VERSION ""

NS_ :

BS_:

BU_:

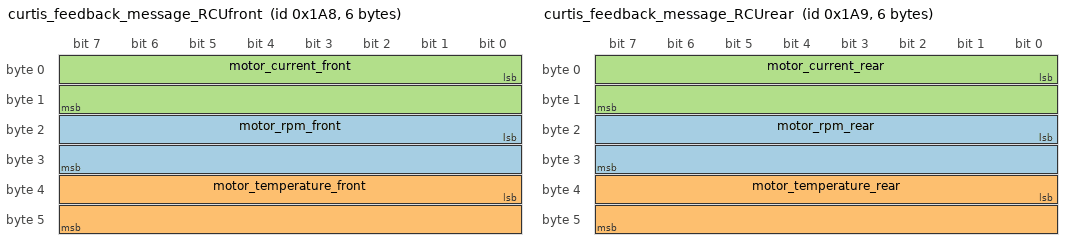
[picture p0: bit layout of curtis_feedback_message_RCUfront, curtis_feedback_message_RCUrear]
BO_ 424 curtis_feedback_message_RCUfront: 6 Vector__XXX
 SG_ motor_rpm_front : 16|16@1- (1,0) [-32768|32767] "rpm" Vector__XXX
 SG_ motor_temperature_front : 32|16@1- (0.1,0) [-100|300] "celsius" Vector__XXX
 SG_ motor_current_front : 0|16@1+ (0.1,0) [0|1000] "A" Vector__XXX

BO_ 425 curtis_feedback_message_RCUrear: 6 Vector__XXX
 SG_ motor_rpm_rear : 16|16@1- (1,0) [-32768|32767] "rpm" Vector__XXX
 SG_ motor_temperature_rear : 32|16@1- (0.1,0) [-100|300] "celsius" Vector__XXX
 SG_ motor_current_rear : 0|16@1+ (0.1,0) [0|1000] "A" Vector__XXX

BO_ 552 curtis_input_message_RCUfront: 8 Vector__XXX
 SG_ rpm_set_front : 0|16@1- (0.0305175781,0) [-1000|1000] "rpm" Vector__XXX

BO_ 553 curtis_input_message_RCUrear: 8 Vector__XXX
 SG_ rpm_set_rear : 0|16@1- (0.0305175781,0) [-1000|1000] "rpm" Vector__XXX

BO_ 0 curtis_input_operational: 8 Vector__XXX
 SG_ pre_operational : 0|8@1+ (1,0) [0|0] "" Vector__XXX

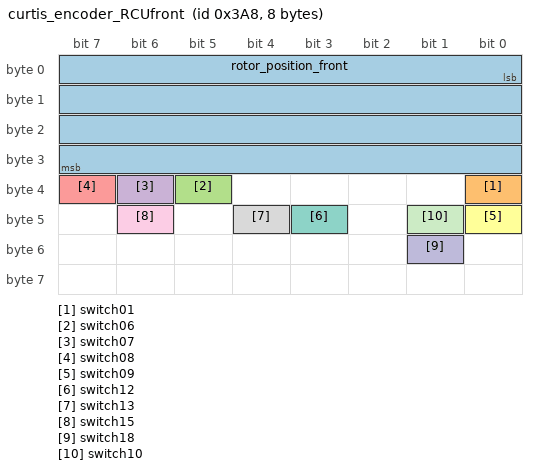
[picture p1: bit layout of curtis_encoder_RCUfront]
BO_ 936 curtis_encoder_RCUfront: 8 Vector__XXX
 SG_ rotor_position_front : 0|32@1- (0.0002441406,0) [-524288|524287] "" Vector__XXX
 SG_ switch01 : 32|1@1+ (1,0) [0|1] "" Vector__XXX
 SG_ switch06 : 37|1@1+ (1,0) [0|1] "" Vector__XXX
 SG_ switch07 : 38|1@1+ (1,0) [0|1] "" Vector__XXX
 SG_ switch08 : 39|1@1+ (1,0) [0|1] "" Vector__XXX
 SG_ switch09 : 40|1@1+ (1,0) [0|1] "" Vector__XXX
 SG_ switch12 : 43|1@1+ (1,0) [0|1] "" Vector__XXX
 SG_ switch13 : 44|1@1+ (1,0) [0|1] "" Vector__XXX
 SG_ switch15 : 46|1@1+ (1,0) [0|1] "" Vector__XXX
 SG_ switch18 : 49|1@1+ (1,0) [0|1] "" Vector__XXX
 SG_ switch10 : 41|1@1+ (1,0) [0|1] "" Vector__XXX

BO_ 937 curtis_encoder_RCUrear: 4 Vector__XXX
 SG_ rotor_position_rear : 0|32@1- (0.000244140625,0) [-524288|524287] "" Vector__XXX

BO_ 1832 controller_status_RCUfront: 1 Vector__XXX
 SG_ controller_mode_front : 0|8@1+ (1,0) [0|255] "" Vector__XXX

BO_ 1833 controller_status_RCUrear: 1 Vector__XXX
 SG_ controller_mode_rear : 0|8@1+ (1,0) [0|255] "" Vector__XXX

BO_ 681 curtis_torque_RCUrear: 8 Vector__XXX
 SG_ motor_torque_rear : 0|32@1- (1,0) [-500|500] "Nm" Vector__XXX
 SG_ motor_power_rear : 32|32@1- (0.1,0) [-100|100] "kW" Vector__XXX

BO_ 680 curtis_torque_RCUfront: 8 Vector__XXX
 SG_ motor_torque_front : 0|32@1- (1,0) [-500|500] "Nm" Vector__XXX
 SG_ motor_power_front : 32|32@1- (0.1,0) [-100|100] "kW" Vector__XXX

CM_ BO_ 424 "RollerConveyorUnit
";
CM_ SG_ 936 switch01 "RCU_CurtainLeftTop";
CM_ SG_ 936 switch06 "RCU_CurtainRightBotton";
CM_ SG_ 936 switch07 "RCU_PalletRightFront";
CM_ SG_ 936 switch08 "RCU_PalletRightRear";
CM_ SG_ 936 switch09 "RCU_PalletLeftFront";
CM_ SG_ 936 switch13 "RCU_CurtainRightTop";
CM_ SG_ 936 switch15 "RCU_CurtainLeftBotton";
CM_ SG_ 936 switch18 "RCU_PalletLeftRear";
BA_DEF_  "BusType" STRING ;
BA_DEF_DEF_  "BusType" "CAN";
SIG_VALTYPE_ 681 motor_torque_rear : 1;
SIG_VALTYPE_ 681 motor_power_rear : 1;
SIG_VALTYPE_ 680 motor_torque_front : 1;
SIG_VALTYPE_ 680 motor_power_front : 1;
